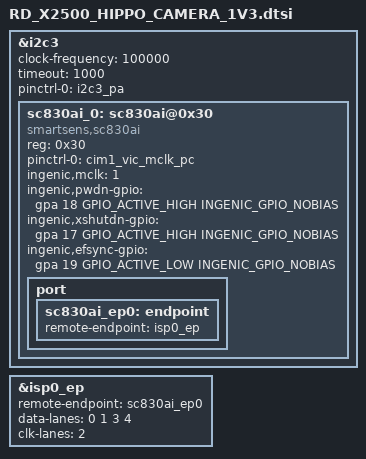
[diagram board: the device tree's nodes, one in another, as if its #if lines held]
#include <generated/autoconf.h>

&i2c3 {
	status = "okay";
	clock-frequency = <100000>;
	timeout = <1000>;
	pinctrl-names = "default";
	pinctrl-0 = <&i2c3_pa>;

#ifdef CONFIG_RD_X2500_HIPPO_CAMERA_1V3_SC830AI
	sc830ai_0:sc830ai@0x30 {
		status = "ok";
		compatible = "smartsens,sc830ai";
		reg = <0x30>;
		pinctrl-names = "default";
		pinctrl-0 = <&cim1_vic_mclk_pc>;

		ingenic,mclk = <1>;
		ingenic,pwdn-gpio = <&gpa 18 GPIO_ACTIVE_HIGH INGENIC_GPIO_NOBIAS>;
		ingenic,xshutdn-gpio = <&gpa 17 GPIO_ACTIVE_HIGH INGENIC_GPIO_NOBIAS>;
		ingenic,efsync-gpio = <&gpa 19 GPIO_ACTIVE_LOW INGENIC_GPIO_NOBIAS>;

		port {
			sc830ai_ep0:endpoint {
				remote-endpoint = <&isp0_ep>;
			};
		};
	};

#elif CONFIG_RD_X2500_HIPPO_CAMERA_1V3_SC531AI
	sc531ai_0:sc531ai@0x30 {
		status = "ok";
		compatible = "smartsens,sc531ai";
		reg = <0x30>;
		pinctrl-names = "default";
		pinctrl-0 = <&cim1_vic_mclk_pc>;

		ingenic,mclk = <1>;
		ingenic,pwdn-gpio = <&gpa 18 GPIO_ACTIVE_HIGH INGENIC_GPIO_NOBIAS>;
		ingenic,xshutdn-gpio = <&gpa 17 GPIO_ACTIVE_HIGH INGENIC_GPIO_NOBIAS>;
		ingenic,efsync-gpio = <&gpa 19 GPIO_ACTIVE_LOW INGENIC_GPIO_NOBIAS>;

		port {
			sc531ai_ep0:endpoint {
				remote-endpoint = <&isp0_ep>;
			};
		};
	};
#endif
};

&isp0_ep {
#ifdef CONFIG_RD_X2500_HIPPO_CAMERA_1V3_SC830AI
	remote-endpoint = <&sc830ai_ep0>;
#elif CONFIG_RD_X2500_HIPPO_CAMERA_1V3_SC531AI
	remote-endpoint = <&sc531ai_ep0>;
#endif
	data-lanes = <0 1 3 4>;
	clk-lanes = <2>;
};

